# A31L21x register map
Vendor: VENDOR ABOV Semiconductor Co., Ltd.; Series: A31L21x; File version: 1.0
CPU: CM0+ r0p1, little endian, no MPU, no FPU, VTOR, 2 interrupt priority bits
Registers are 32-bit, read-write, reset 0x0 unless marked. A register's access mark holds for its fields unless they carry their own. Offsets are from the block's base; [hi:lo] are bit positions; {n}, {i} and the like mark numbered series.

## TIMER6n — Timer/Counter 6n
Base 0x56000000
Same registers: TIMER60 0x40002F00
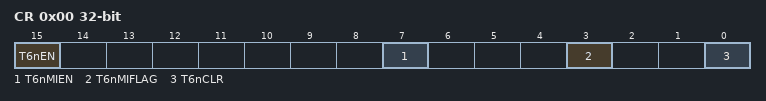
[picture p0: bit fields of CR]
0x00 CR — TIMER6n Control Register
  [15] T6nEN — TIMER6n Operation Enable
    0=Disable timer 60 operation and 100Hz RC oscillator; 1=Enable timer 60 operation and 100Hz RC oscillator
  [7] T6nMIEN — TIMER6n Match Interrupt Enable
    0=Disable the match interrupt; 1=Enable the match interrupt
  [3] T6nMIFLAG — TIMER6n Match Interrupt Flag
    0=No request occurred; 1=Request occurred. This bit is cleared to '0' when write '1'.
  [0] T6nCLR — TIMER6n Counter Clear
    0=NoEffect; 1=Clear Counter. (Automatically cleared to '0' after operation)
0x04 DR reset 0xFFFF — TIMER6n Data Register
  [15:0] DATA — TIMER6n Data
0x08 CNT ro — TIMER6n Counter Register
  [15:0] CNT — TIMER6n Counter

## UARTn
Base 0x58000000
Same registers: UART0 0x40004000
0x00 RBR ro — UARTn Receive Data Buffer Register
  [7:0] RBR — UARTn Receive Data Buffer
0x00 THR wo — UARTn Transmit Data Hold Register
  [7:0] THR — UARTn Transmit Data Hold
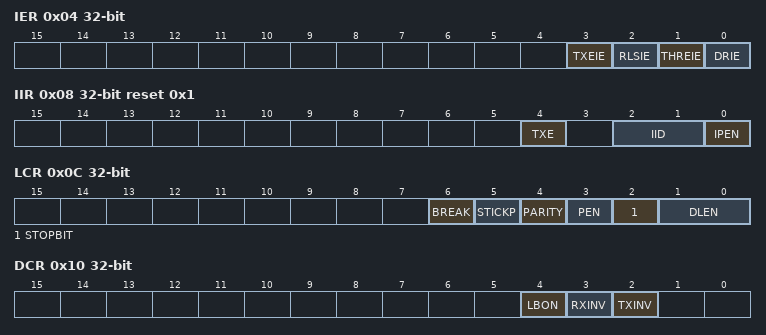
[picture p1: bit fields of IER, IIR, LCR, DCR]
0x04 IER — UARTn Interrupt Enable Register
  [3] TXEIE — Transmit Empty Interrupt Enable
  [2] RLSIE — Receiver Line Status Interrupt Enable
  [1] THREIE — Transmit Holding Register Empty Interrupt Enable
  [0] DRIE — Data Receive Interrupt Enable
0x08 IIR ro reset 0x1 — UARTn Interrupt ID Register
  [4] TXE — Transmit Complete Interrupt Source ID
  [2:1] IID — UARTn Interrupt ID
  [0] IPEN — Interrupt Pending
0x0C LCR — UARTn Line Control Register
  [6] BREAK — Transfer Break Control
  [5] STICKP — Force Parity
  [4] PARITY — Parity Mode and Parity Stuck Selection
  [3] PEN — Parity Bit Transfer Enable
  [2] STOPBIT — Stop Bit Length Selection
  [1:0] DLEN — Data Length Selection
0x10 DCR — UARTn Data Control Register
  [4] LBON — Local Loopback Test Mode Enable
  [3] RXINV — Receive Data Inversion Selection
  [2] TXINV — Transmit Data Inversion Selection
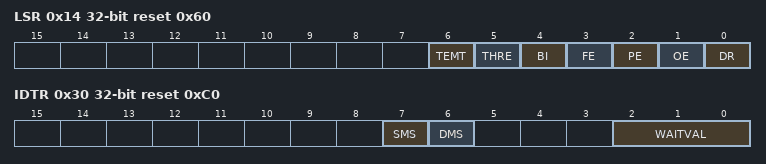
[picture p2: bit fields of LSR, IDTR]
0x14 LSR ro reset 0x60 — UARTn Line Status Register
  [6] TEMT — Transmit Empty
  [5] THRE — Transmit Holding Empty
  [4] BI — Break Condition Indication
  [3] FE — Frame Error Indicator
  [2] PE — Parity Error Indicator
  [1] OE — Overrun Error Indicator
  [0] DR — Data Receive Indicator
0x20 BDR — UARTn Baud Rate Divisor Latch Register
  [15:0] BDR — Baud Rate Divider Latch Value. Baud rate = fUARTnCLK/(16 x BDR[15:0] x 2)
0x24 BFR — UARTn Baud Rate Fractional Counter Value
  [7:0] BFR — Fraction Counter value
    0=Disable fraction counter
0x30 IDTR reset 0xC0 — UARTn Inter-frame Delay Time Register
  [7] SMS — Start Bit Multi Sampling Enable
  [6] DMS — Data Bit Multi sampling enable
  [2:0] WAITVAL — Wait Time Value

## LPUARTn — Low Power UART n
Base 0x59000000
Same registers: LPUART0 0x40005C00, LPUART1 0x40005C80
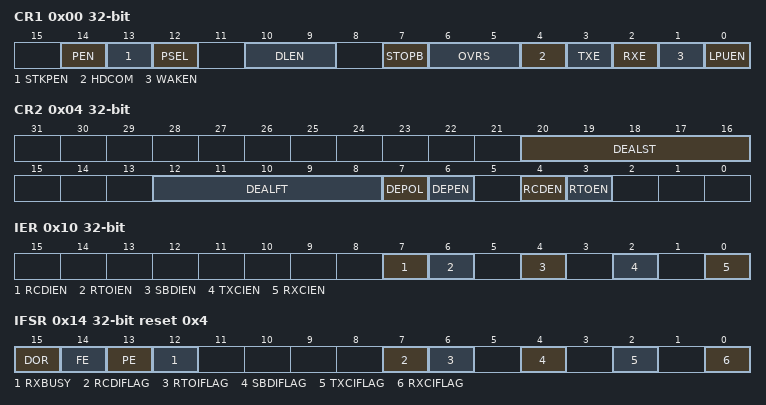
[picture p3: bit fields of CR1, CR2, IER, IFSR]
0x00 CR1 — LPUARTn Control Register 1
  [14] PEN — Parity Enable
  [13] STKPEN — Stick Parity Enable
  [12] PSEL — Parity Selection
  [10:9] DLEN — Data Length Selection
  [7] STOPB — Stop
  [6:5] OVRS — Oversampling Selection
  [4] HDCOM — 1-wire Half-Duplex Communication
  [3] TXE — Enable the transmitter unit.
  [2] RXE — Enable the receiver unit.
  [1] WAKEN — Wake-Up Function bit in Deep Sleep Mode
  [0] LPUEN — Low Power UART Enable
0x04 CR2 — LPUARTn Control Register 2
  [20:16] DEALST — DE Pin Active Level Start Time
  [12:8] DEALFT — DE Pin Active Level Finish Time
  [7] DEPOL — DE Pin Polarity Selection
  [6] DEPEN — DE Pin Function Enable
  [4] RCDEN — Receive Character Detection Function Enable
  [3] RTOEN — Receive Time Out Function Enable
0x10 IER — LPUARTn Interrupt Enable Register
  [7] RCDIEN — Receive Character Detection Interrupt Enable
  [6] RTOIEN — Receive Time Out Interrupt Enable
  [4] SBDIEN — Start Bit Detection Interrupt Enable bit in Deep Sleep Mode
  [2] TXCIEN — Transmit Complete Interrupt Enable
  [0] RXCIEN — Receive Data Register Not Empty Interrupt Enable
0x14 IFSR reset 0x4 — LPUARTn Interrupt Flag and Status Register
  [15] DOR — Data Overrun
  [14] FE — Frame Error
  [13] PE — Parity Error
  [12] RXBUSY ro — RXD Line Busy
  [7] RCDIFLAG — Receive Character detection Interrupt Flag
  [6] RTOIFLAG — Receive Time Out Interrupt Flag
  [4] SBDIFLAG — Start Bit Detection Interrupt Flag
  [2] TXCIFLAG — Transmit Complete Interrupt Flag
  [0] RXCIFLAG — Receive Data Register Not Empty Interrupt Flag
0x18 RDR ro — LPUARTn Receive Data Register
  [7:0] RDATA — Receive Data
0x1C TDR — LPUARTn Transmit Data Register
  [7:0] TDATA — Transmit Data
0x20 BDR reset 0xFFFF — LPUARTn Baud Rate Data Register
  [15:0] BDATA — These bits are used to generate baud rate
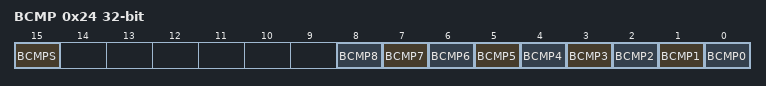
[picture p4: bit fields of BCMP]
0x24 BCMP — LPUARTn Baud Rate Compensation Register
  [15] BCMPS — Baud Rate Compensation Sign
  [n] BCMP{n} (n=0..8) — Baud Rate Compensation {n}
0x28 RTODR reset 0xFFFF — LPUARTn Receive Time Out Data Register
  [23:0] RTOD — LPUARTn Receive Time Out Data
0x2C RCDR — LPUARTn Receive Character Detection Data Register
  [7:0] RCDD — LPUARTn Receive Character Detection Data
0x30 DLYDR — LPUARTn Tx Delay Time Data Register
  [7:0] DLYD — LPUARTn Tx Delay Data
